# cslr_srio register map
Vendor: Texas Instruments
Registers are 32-bit, access not given, reset 0x0 unless marked. A register's access mark holds for its fields unless they carry their own. Offsets are as the file gives them; [hi:lo] are bit positions; {n}, {i} and the like mark numbered series.

## SRIO (part 2 of 2) — Rapid input/output
0x104C PE_LL_CTL reset 0x1 — Processing Element Logical Layer Control CSR
  [2:0] EXTENDED_ADDRESSING_CONTROL rw — Controls the number of address bits generated by the PE as a source and processed by the PE as the target of an operation. 0b100 - PE supports 66 bit addresses 0b010 - PE supports 50 bit addresses 0b001 - PE supports 34 bit addresses (default) All other encodings reserved
    4=66BIT (PE supports 66 bit addresses); 2=50BIT (PE supports 50 bit addresses); 1=34BIT (PE supports 34 bit addresses)
0x1058 LCL_CFG_HBAR — Local Configuration Space Base Address 0 CSR
  [30:0] LCSBA ro — For bits 30 to 15 Reserved for 34b addresses Reserved for 50b addresses Bits 66-51 of a 66b address For bits 14 to 0 Reserved for 34b addresses Bits 50-36 of a 50b address Bits 50-36 of a 66b address
0x105C LCL_CFG_BAR ro — Local Configuration Space Base Address 1 CSR
  [31:0] LCSBA — For bit 31 Reserved for 34b addresses Bit 35 of a 50b address Bit 35 of a 66b address For bits 30 to 0 Bits 34-3 of a 34b address, Bits 35-3 of a 50b address Bits 35-3 of a 66b address
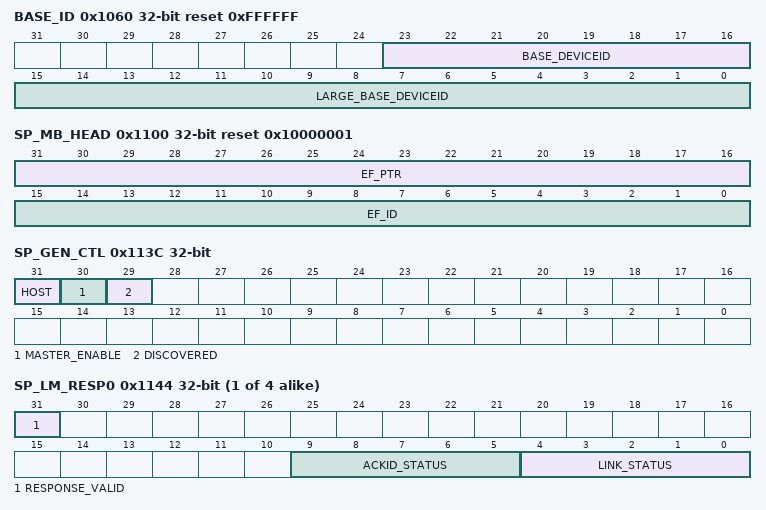
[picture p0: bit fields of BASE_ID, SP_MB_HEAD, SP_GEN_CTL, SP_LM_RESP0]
0x1060 BASE_ID reset 0xFFFFFF — Base Device ID CSR
  [23:16] BASE_DEVICEID rw — This is the base ID of the device in small common transport system (End points only)
  [15:0] LARGE_BASE_DEVICEID rw — This is the base ID of the device in a large common transport system (Only valid for end points, and if bit 4 of the PEFTR register is set)
0x1068 HOST_BASE_ID_LOCK reset 0xFFFF — Host Base Device ID Lock CSR
  [15:0] HOST_BASE_DEVICEID rw — This is the base ID for the Host PE that is initializing this PE
0x106C COMP_TAG rw — Component Tag CSR
  [31:0] COMPONENT_TAG — Software defined component Tag for PE. Useful for devices without device IDs
0x1100 SP_MB_HEAD ro reset 0x10000001 — 1x/4x LP-Serial Port Maintenance Block Header
  [31:16] EF_PTR — Hard wired pointer to the next block in the data structure.
  [15:0] EF_ID — Hard-wired extended features ID, 0x0001 - general endpoint device 0x0002 - general endpoint device with software assisted error recovery option. 0x0003 - Switch
0x1120 SP_LT_CTL reset 0xFFFFFF00 — Port Link Time-Out Control CSR
  [31:8] TIMEOUT_VALUE rw — Timeout value for all ports on the device. This timeout is for link events such as sending a packet to receiving the corresponding ACK. Max value represents 3-6 seconds.Timeout duration = 205nS * Timeout Value; Where, Timeout value is the decimal representation of this register value. FFFFFFh = 3.4 seconds 0FFFFFh = 215 ms 00FFFFh = 13.4 ms 000FFFh = 839.5 us 0000FFh = 52.3 us 00000Fh = 3.1 us 000001h = 205 ns for simulation only 000000h = Timer disabled
0x1124 SP_RT_CTL reset 0xFFFFFF00 — Port Response Time-Out Control CSR
  [31:8] TIMEOUT_VALUE rw — Timeout value for all ports on the device. This timeout is for sending a packet to receiving the corresponding response packet. Max value represents 3-6 seconds. The timeout duration can be expressed as:Timeout = 15 * ((Prescale value + 1) * DMA clock period * Timeout Value) Where, Prescale value is set in 0x0020 PSCR and the Timeout value is the decimal representation of this register value.
0x113C SP_GEN_CTL — Port General Control CSR
  [31] HOST rw — A Host device is a device that is responsible for system exploration, initialization, and maintenance. Agent or slave devices are typically initialized by Host devices. 0b0 - agent or slave device 0b1  host device
    0=DISABLE (Agent or Slave device); 1=ENABLE (Host device)
  [30] MASTER_ENABLE rw — The Master Enable bit controls whether or not a device is allowed to issue requests into the system. If the Master Enable is not set, the device may only respond to requests. 0b0 - processing element cannot issue requests 0b1 - processing element can issue requests
  [29] DISCOVERED rw — This device has been located by the processing element responsible for system configuration 0b0 - The device has not been previously discovered 0b1 - The device has been discovered by another processing element
{0x1140+0x20*i} SP_LM_REQ{i} (i=0..3) — Port Link Maintenance Request CSR
  [2:0] COMMAND rw — A write to this register generates a link-request control symbol on the corresponding port interface. Command to be sent in the link-request control symbol. If read, this field returns the last written value
{0x1144+0x20*i} SP_LM_RESP{i} (i=0..3) — Port Link Maintenance Response CSR
  [31] RESPONSE_VALID ro — If the link-request causes a link-response, this bit indicates that the link-response has been received and the status fields are valid.If the link-request does not cause a link-response, this bit indicates that the link-request has been transmitted.This bit automatically clears on read.
  [9:5] ACKID_STATUS ro — ackID status field from the link-response control symbol
  [4:0] LINK_STATUS ro — link status field from the link-response control symbol
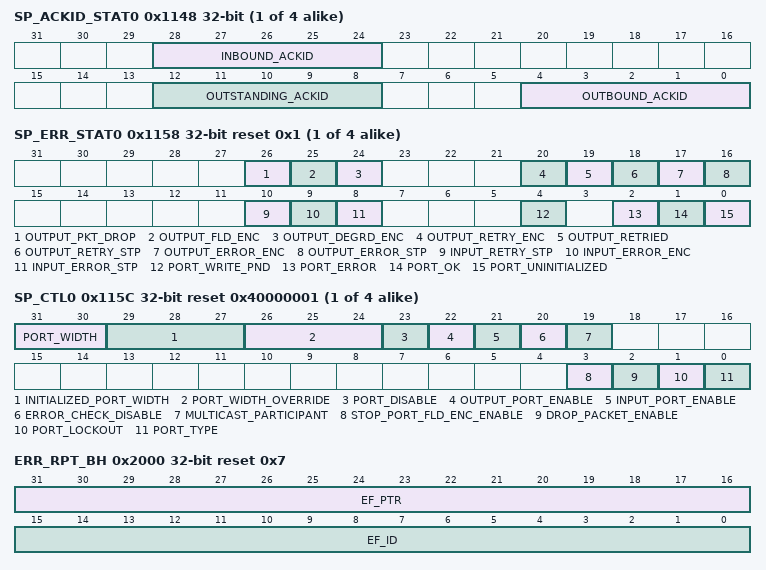
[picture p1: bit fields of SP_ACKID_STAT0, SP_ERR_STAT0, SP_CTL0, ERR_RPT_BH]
{0x1148+0x20*i} SP_ACKID_STAT{i} (i=0..3) — Port Local AckID Status CSR
  [28:24] INBOUND_ACKID rw — Input port next expected ackID value
  [12:8] OUTSTANDING_ACKID rw — Output port unacknowledged ackID status. Next expected acknowledge control symbol ackID field that indicates the ackID value expected in the next received acknowledge control symbol
  [4:0] OUTBOUND_ACKID rw — Output port next transmitted ackID value. Software writing this value can force retransmission of outstanding unacknowledged packets in order to manually implement error recovery
{0x1158+0x20*i} SP_ERR_STAT{i} reset 0x1 (i=0..3) — Port Error and Status CSR
  [26] OUTPUT_PKT_DROP rw — Output port has discarded a packet. (switch devices only)
  [25] OUTPUT_FLD_ENC rw — Output port has encountered a failed condition, meaning that the failed port error threshold has been reached in the Port n Error Rate Threshold register. Once set remains set until written with a logic 1 to clear
  [24] OUTPUT_DEGRD_ENC rw — Output port has encountered a degraded condition, meaning that the degraded port error threshold has been reached in the Port n Error Rate Threshold register. Once set remains set until written with a logic 1 to clear.
  [20] OUTPUT_RETRY_ENC rw — Output port has encountered a retry condition.This bit is set when bit 18 is set. Once set, remains set until written with a logic 1 to clear.
  [19] OUTPUT_RETRIED ro — Output port has received a packet-retry control symbol and can not make forward progress. This bit is set when bit 18 is set and is cleared when a packet-accepted or a packet-not-accepted control symbol is received (read-only).
  [18] OUTPUT_RETRY_STP ro — Output port has received a packet-retry control symbol and is in the "output retry-stopped" state (read-only).
  [17] OUTPUT_ERROR_ENC rw — Output port has encountered (and possibly recovered from) a transmission error. This bit is set when bit 16 is set. Once set, remains set until written with a logic 1 to clear
  [16] OUTPUT_ERROR_STP ro — Output is in the "output error-stopped" state (read-only).
  [10] INPUT_RETRY_STP ro — Input port is in the "input retry-stopped" state (read-only).
  [9] INPUT_ERROR_ENC rw — Input port has encountered (and possibly recovered from) a transmission error. This bit is set when bit 8 is set. Once set, remains set until written with a logic 1 to clear
  [8] INPUT_ERROR_STP ro — Input port is in the "input error-stopped" state (read-only).
  [4] PORT_WRITE_PND rw — Port has encountered a condition which required it to initiate a Maintenance Port-write operation This bit is only valid if the device is capable of issuing a maintenance port-write transaction. Once set remains set until written with a logic 1 to clear.
  [2] PORT_ERROR rw — Input or output port has encountered an error from which hardware was unable to recover. Once set, remains set until written with a logic 1 to clear.
  [1] PORT_OK ro — The input and output ports are initialized and the port is exchanging error-free control symbols with the attached device (read-only).
  [0] PORT_UNINITIALIZED ro — Input and output ports are not initialized. This bit and bit 1 are mutually exclusive (read-only
{0x115C+0x20*i} SP_CTL{i} reset 0x40000001 (i=0..3) — Port Control CSR
  [31:30] PORT_WIDTH ro — Hardware width of the port(read-only): 0b00 - Single-lane port 0b01 - Four-lane port 0b10 - 0b11  Reserved Only 0b00 is valid for SP1, SP2, and SP3
  [29:27] INITIALIZED_PORT_WIDTH ro — Width of the ports after initialized (read only): 0b000 - Single-lane port, lane 0 0b001 - Single-lane port, lane 2 0b010 - Four-lane port 0b011 - 0b111 - Reserved
  [26:24] PORT_WIDTH_OVERRIDE rw — Soft port configuration to override the hardware size: 0b000 - No override 0b001 - Reserved 0b010 - Force single lane, lane 0 0b011 - Force single lane, lane 2 0b100 - 0b111 - Reserved
    0=NO_OVERRIDE; 2=SINGLE_LANE_0 (Force single lane, lane 0); 3=SINGLE_LANE_2 (Force single lane, lane 2)
  [23] PORT_DISABLE rw — 0b0 - port receivers/drivers are enabled 0b1 - port receivers/drivers are disabled and are unable to receive/transmit to any packets or control symbols
  [22] OUTPUT_PORT_ENABLE rw — 0b0 - port is stopped and not enabled to issue any packets except to route or respond to I/O logical MAINTENANCE packets, depending upon the functionality of the processing element. Control symbols are not affected and are sent normally. 0b1 - port is enabled to issue any packets
  [21] INPUT_PORT_ENABLE rw — Input port receive enable: 0b0 - port is stopped and only enabled to route or respond I/O logical MAINTENANCE packets, depending upon the functionality of the processing element 0b1 - port is enabled to respond to any packet
  [20] ERROR_CHECK_DISABLE rw — This bit disables all RapidIO transmission error checking0b0 - Error checking and recovery is enabled 0b1 - Error checking and recovery is disabled
  [19] MULTICAST_PARTICIPANT ro — Send incoming Multi cast-event control symbols to this port (multiple port devices only)
  [3] STOP_PORT_FLD_ENC_ENABLE rw — When set, this bit causes the port to set the Port Error bit in the Port n Error and Status CSR and stop attempting to send packets to the connected device when the Output Failed-encountered bit is set. Packets are discarded if the Drop Packet Enable bit is set. When cleared the port continues to attempt to transmit packets to the connected device if the Output Failed-encountered bit is set.
  [2] DROP_PACKET_ENABLE rw — When set this bit allows the output port to drop packets that are acknowledged with a packet-not-accepted control symbol when the error failed threshold is exceeded. If the port "heals", and the current error rate falls below the failed threshold, the output no longer drops packets. (switch devices only) When cleared, the output port continues to try to transmit packets that have been rejected due to transmission errors
  [1] PORT_LOCKOUT rw — Port Lockout:When cleared, this port is enabled to issue any packets When set, this port is stopped and is not enabled to issue or receive any packets; the input port can still follow the training procedure and can still send and respond to link-requests; all received packets return packet-not-accepted control symbols to force an error condition to be signaled by the sending device
  [0] PORT_TYPE ro — This indicates the port type, parallel or serial (read only) 0b0 - Parallel port 0b1 - Serial port
0x2000 ERR_RPT_BH ro reset 0x7 — Error Reporting Block Header
  [31:16] EF_PTR — Hard wired pointer to the next block in the data structure. NONE EXISTS
  [15:0] EF_ID — Hard wired Extended Features ID
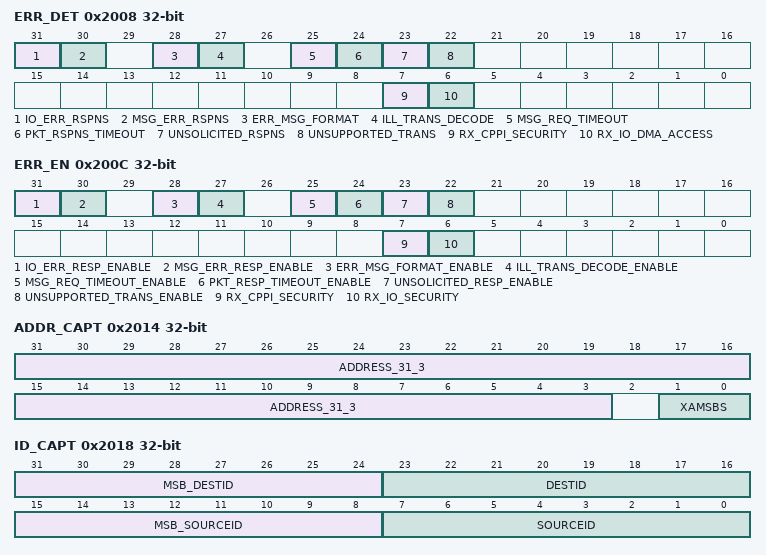
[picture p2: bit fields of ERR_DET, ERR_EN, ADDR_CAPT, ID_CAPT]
0x2008 ERR_DET — Logical/Transport Layer Error Detect CSR
  [31] IO_ERR_RSPNS rw — Received a response of 'ERROR' for an IO Logical Layer Request. (end point device only) Write 0 to clear
  [30] MSG_ERR_RSPNS rw — Received a response of 'ERROR' for an MSG Logical Layer Request. (end point device only) Write 0 to clear
  [28] ERR_MSG_FORMAT rw — Received MESSAGE packet data payload with an invalid size or segment (MSG logical) (end point device only)Write 0 to clear
  [27] ILL_TRANS_DECODE rw
  [25] MSG_REQ_TIMEOUT rw — A required message request has not been received within the specified time-out interval (MSG logical) (end point device only) Write 0 to clear
  [24] PKT_RSPNS_TIMEOUT rw — A required response has not been received within the specified timeout interval (IO/MSG/GSM logical) (end point device only) Write 0 to clear
  [23] UNSOLICITED_RSPNS rw — An unsolicited/unexpected Response packet was received (IO/MSG/GSM logical; only Maintenance response for switches) (switch or endpoint device) Write 0 to clear
  [22] UNSUPPORTED_TRANS rw — A transaction is received that is not supported in the Destination Operations CAR (IO/MSG/GSM logical; only Maintenance port-write for switches) (switch or endpoint device) Write 0 to clear
  [7] RX_CPPI_SECURITY rw — Access to one of the RX queues was blocked Write 0 to clear
  [6] RX_IO_DMA_ACCESS rw — DMA access to MAU was blocked Write 0 to clear
0x200C ERR_EN — Logical/Transport Layer Error Enable CSR
  [31] IO_ERR_RESP_ENABLE rw — Enable reporting of an IO error response. Save and Lock capture information in appropriate Logical/Transport Layer Capture CSRs. (end point device only)
  [30] MSG_ERR_RESP_ENABLE rw — Enable reporting of a Message error response. Save and Lock capture information in appropriate Logical/Transport Layer Capture CSRs.(end point device only)
  [28] ERR_MSG_FORMAT_ENABLE rw — Enable reporting of a message format error. Save and lock transaction capture information in Logical/Transport Layer Device ID and Control Capture CSRs. (end point device only)
  [27] ILL_TRANS_DECODE_ENABLE rw — Enable reporting of an illegal transaction decode error. Save and Lock capture information in Logical/Transport Layer Device ID and Control Capture CSRs. (switch or end-point device)
  [25] MSG_REQ_TIMEOUT_ENABLE rw — Enable reporting of a Message Request time-out error. Save and lock transaction capture information in Logical/Transport Layer Device ID and Control Capture CSRs for the last Message request segment packet received. (end point device only)
  [24] PKT_RESP_TIMEOUT_ENABLE rw — Enable reporting of a packet response time-out error. Save and lock original request address in Logical/Transport Layer Address Capture CSRs. Save and lock original request Destination ID in Logical/Transport Layer Device ID Capture CSR. (end point device only).
  [23] UNSOLICITED_RESP_ENABLE rw — Enable reporting of an unsolicited response error. Save and Lock capture information in Logical/Transport Layer Device ID and Control Capture CSRs. (switch or end-point device)
  [22] UNSUPPORTED_TRANS_ENABLE rw — Enable reporting of an unsupported transaction error. Save and Lock capture information in Logical/Transport Layer Device ID and Control Capture CSRs. (switch or end-point device)
  [7] RX_CPPI_SECURITY rw — Enable reporting of attempt at unauthorized access to a RX queue. Save and Lock capture information in appropriate Logical/Transport Layer Capture CSRs.
  [6] RX_IO_SECURITY rw — Enable reporting of attempt at unauthorized memory location access. Save and Lock capture information in appropriate Logical/Transport Layer Capture CSRs.
0x2010 H_ADDR_CAPT ro — Logical/Transport Layer High Address Capture CSR
  [31:0] ADDRESS_63_32 — Most Significant 32 bits of the address associated with the error(only valid for devices supporting 66 and 50 bit addresses)
0x2014 ADDR_CAPT — Logical/Transport Layer Address Capture CSR
  [31:3] ADDRESS_31_3 ro — Least Significant 29 bits of the address associated with the error
  [1:0] XAMSBS ro — Extended address bits of the address associated with the error
0x2018 ID_CAPT ro — Logical/Transport Layer Device ID Capture CSR
  [31:24] MSB_DESTID — Most significant byte of the destinationID associated with the error (large transport systems only)
  [23:16] DESTID — The destinationID associated with the error
  [15:8] MSB_SOURCEID — Most significant byte of the source ID associated with the error (large transport systems only)
  [7:0] SOURCEID — The sourceID associated with the error
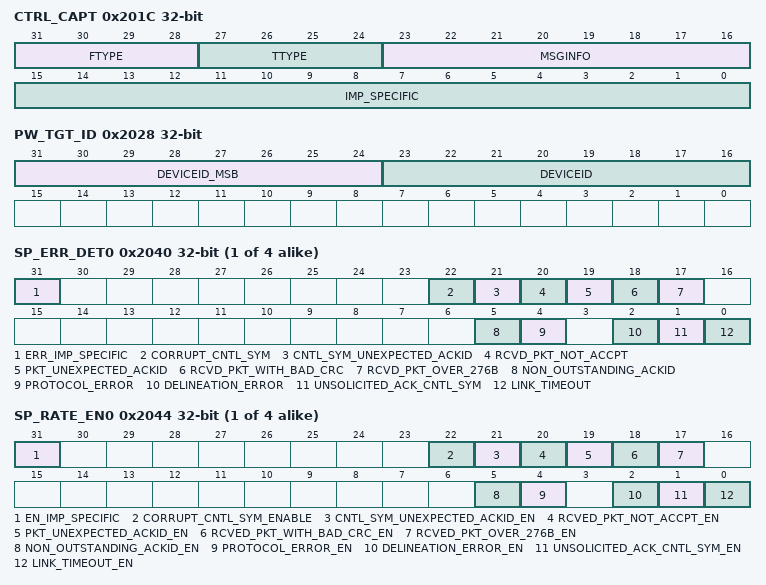
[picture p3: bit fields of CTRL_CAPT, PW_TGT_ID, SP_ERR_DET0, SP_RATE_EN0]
0x201C CTRL_CAPT ro — Logical/Transport Layer Control Capture CSR
  [31:28] FTYPE — Format type associated with the error
  [27:24] TTYPE — Transaction type associated with the error
  [23:16] MSGINFO — letter, mbox, and msgseg for the last Message request received for the mailbox that had an error (Message errors only)
  [15:0] IMP_SPECIFIC — Implementation specific information associated with the error
0x2028 PW_TGT_ID — Port-Write Target Device ID CSR
  [31:24] DEVICEID_MSB rw — This is the most significant byte of the port-write target device ID (large transport systems only)
  [23:16] DEVICEID rw — This is the port-write target deviceID
{0x2040+0x40*i} SP_ERR_DET{i} (i=0..3) — Port Error Detect CSR
  [31] ERR_IMP_SPECIFIC rw — An implementation specific error has been detected. It covers illegal field of Maintenance packet error, illegal destination ID, not supported transaction.
  [22] CORRUPT_CNTL_SYM rw — Received a control symbol with a bad CRC value (serial)
  [21] CNTL_SYM_UNEXPECTED_ACKID rw — Received an acknowledge control symbol with an unexpected ackID (packet-accepted or packet_retry). The Capture registers don't have valid information during this error detection
  [20] RCVD_PKT_NOT_ACCPT rw — Received packet-not-accepted acknowledge control symbol
  [19] PKT_UNEXPECTED_ACKID rw — Received packet with unexpected ackID value - out-of-sequence ackID
  [18] RCVD_PKT_WITH_BAD_CRC rw — Received packet with a bad CRC value
  [17] RCVD_PKT_OVER_276B rw — Received packet which exceeds the maximum allowed size
  [5] NON_OUTSTANDING_ACKID rw — Link_response received with an ackID that is not outstanding. The Capture registers don't have valid information during this error detection
  [4] PROTOCOL_ERROR rw — An unexpected packet or control symbol was received
  [2] DELINEATION_ERROR ro — Received unaligned /SC/ or /PD/ or undefined code-group (serial). The Capture registers don't have valid information during this error detection
  [1] UNSOLICITED_ACK_CNTL_SYM rw — An unexpected acknowledge control symbol was received
  [0] LINK_TIMEOUT rw — An acknowledge or link-response control symbol is not received within the specified time-out interval. The Capture registers don't have valid information during this error detection.
{0x2044+0x40*i} SP_RATE_EN{i} (i=0..3) — Port Error Enable CSR
  [31] EN_IMP_SPECIFIC rw — Enable error rate counting of implementation specific errors
  [22] CORRUPT_CNTL_SYM_ENABLE rw — Enable error rate counting of a corrupt control symbol
  [21] CNTL_SYM_UNEXPECTED_ACKID_EN rw — Enable error rate counting of an acknowledge control symbol with an unexpected ackID
  [20] RCVED_PKT_NOT_ACCPT_EN rw — Enable error rate counting of received packet-not-accepted control symbols
  [19] PKT_UNEXPECTED_ACKID_EN rw — Enable error rate counting of packet with unexpected ackID value - out-of-sequence ackID
  [18] RCVED_PKT_WITH_BAD_CRC_EN rw — Enable error rate counting of packet with a bad CRC value
  [17] RCVED_PKT_OVER_276B_EN rw — Enable error rate counting of packet which exceeds the maximum allowed size
  [5] NON_OUTSTANDING_ACKID_EN rw — Enable error rate counting of link-responses received with an ackID that is not outstanding
  [4] PROTOCOL_ERROR_EN rw — Enable error rate counting of protocol errors
  [2] DELINEATION_ERROR_EN rw — Enable error rate counting of delineation errors
  [1] UNSOLICITED_ACK_CNTL_SYM_EN rw — Enable error rate counting of unsolicited acknowledge control symbol errors
  [0] LINK_TIMEOUT_EN rw — Enable error rate counting of link time-out errors
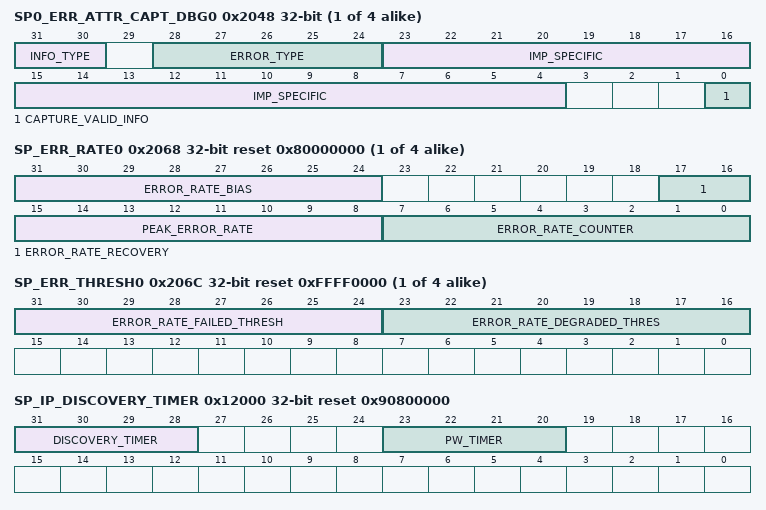
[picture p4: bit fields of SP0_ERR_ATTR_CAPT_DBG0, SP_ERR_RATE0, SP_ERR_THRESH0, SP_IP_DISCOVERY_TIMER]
{0x2048+0x40*i} SP{i}_ERR_ATTR_CAPT_DBG0 (i=0..3) — Port Attributes Error Capture CSR
  [31:30] INFO_TYPE ro — Type of information logged 00 - packet 01 - control symbol (only error capture register 0 is valid) 10 - implementation specific (capture register contents are implementation specific) 11 - undefined (S-bit error), capture as if a packet (parallel physical layer only)
  [28:24] ERROR_TYPE ro — Encoded value of captured error bit in the Port n Error Detect Register
  [23:4] IMP_SPECIFIC ro — Implementation Dependent Error Information
  [0] CAPTURE_VALID_INFO rw — This bit is set by hardware to indicate that the Packet/control symbol capture registers contain valid information. For control symbols, only capture register 0 will contain meaningful information. The software write "0" to clear this bit and subsequently unlock all capture registers of port n
{0x204C+0x40*i} SP{i}_ERR_CAPT_DBG[4] ro (i=0..3) — Port Packet/Control Symbol Error Capture CSR
  [31:0] CAPTURE — Control Character and Control Symbol or 0 to 3 Bytes of Packet Header
{0x2068+0x40*i} SP_ERR_RATE{i} reset 0x80000000 (i=0..3) — Port Error Rate CSR
  [31:24] ERROR_RATE_BIAS rw — These bits provide the error rate bias value 0x00 - do not decrement the error rate counter 0x01 - decrement every 1ms (nominal) 0x03 - decrement every 10ms (nominal) 0x07 - decrement every 100ms 0x0F - decrement every 1s (nominal) 0x1F - decrement every 10s (nominal) 0x3F - decrement every 100s (nominal) 0x7F - decrement every 1000s (nominal) 0xFF - decrement every 10000s (nominal) other values are reserved
  [17:16] ERROR_RATE_RECOVERY rw — These bits limit the incrementing of the error rate counter above the failed threshold trigger.0b00 - only count 2 errors above 0b01 - only count 4 errors above 0b10 - only count 16 error above 0b11 - do not limit incrementing the error rate count
  [15:8] PEAK_ERROR_RATE rw — This field contains the peak value attained by the error rate counter
  [7:0] ERROR_RATE_COUNTER rw — These bits maintain a count of the number of transmission error that have occurred. If this value equals the value contained in the error rate threshold trigger register, then an error will be reported.
{0x206C+0x40*i} SP_ERR_THRESH{i} reset 0xFFFF0000 (i=0..3) — Port Error Rate Threshold CSR
  [31:24] ERROR_RATE_FAILED_THRESH rw — These bits provide the threshold value for reporting an error condition due to a possibly broken link.0x00 - Disable the error rate register 0x01 - Set the error reporting threshold to 1 0x02 - Set the error reporting threshold to 2 ... 0xFF - Set the error reporting threshold to 255
  [23:16] ERROR_RATE_DEGRADED_THRES rw — These bits provide the threshold value for reporting an error condition due to a degrading link.0x00 - Disable the error rate register 0x01 - Set the error reporting threshold to 1 0x02 - Set the error reporting threshold to 2 ... 0xFF - Set the error reporting threshold to 255
0x12000 SP_IP_DISCOVERY_TIMER reset 0x90800000 — Port IP Discovery Timer in 4x mode
  [31:28] DISCOVERY_TIMER rw — Discovery Timer in 4x mode. The discovery-timer allows time for the link partner to enter its DISCOVERY state and if the link partner is supporting 4x mode, for all 4 lanes to be aligned. 0000b: 102.4pS, for debug only 0001b: 0.84ms 0010b: 0.84ms * 2 = 1.68ms .. 1001b: 0.84ms * 9= 7.56ms (default) ... 1111b: 0.84ms *15= 12.6ms
  [23:20] PW_TIMER rw — Port-Write Timer . The timer defines a period to repeat sending an error reporting Port-Write request for software assistance. The timer stopped by software writing to the error detect registers 0000b: Disabled. Port-Write is sent once only 0001b: 107ms - 214ms 0010b: 214ms - 321ms 0100b: 428ms - 535ms 1000b: 856ms - 963ms (default) 1111b: 0.82-1.64us -for debug only Other  reserved
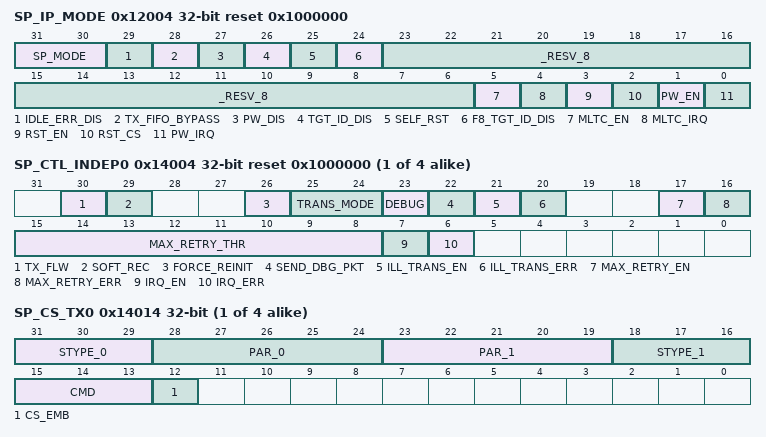
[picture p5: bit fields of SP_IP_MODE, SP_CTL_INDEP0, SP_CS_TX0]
0x12004 SP_IP_MODE reset 0x1000000 — Port IP Mode CSR
  [31:30] SP_MODE ro — SRIO Port IP Mode of operation: 00 - 1x/4x LP-Serial RapidIO Specification 01 - 4 ports (1x mode each) 10 - reserved 11 - reserved
  [29] IDLE_ERR_DIS rw — IDLE Error checking disable 1 - error checking disabled, all not idle or invalid characters during idle sequence are ignored 0 - error checking enabled (default), only |K|, |A| and |R| characters are available. If input receive any other characters in idle sequence it should enter the Input-Error-stopped state
    1=DISABLE (Error checking disabled); 0=ENABLE (Error checking enabled)
  [28] TX_FIFO_BYPASS rw — TX_ FIFO_BYPASS 0  The TX_FIFO is operational (Default) 1 - Transmit FIFO is bypassed The txbclk and the sys_clk maust be locked during operation, but the phase variation up to 1 clock cycle is allowable. The 4 deep FIFO is used to accommodate the phase difference
    0=DISABLE (The TX_FIFO is operational (Default)); 1=ENABLE (The TX_FIFO is bypassed)
  [27] PW_DIS rw — Port_Write Disable 0 = Port-Write Error reporting is enabled(default) 1 = Port-Write is disabled
    1=DISABLE (Disable Port-Write Error reporting); 0=ENABLE (Enable Port-Write Error reporting)
  [26] TGT_ID_DIS ro — Destination ID Decode Disable - Definition of packet acception by the physical layer 0 -packet accepted if DestID = Base ID When DestID is not equal to Base ID, the packet is ignored, i.e. it accepted by RapidIO port but is not forwarded to logical layer 1 - packet accepted with any DestID and forwarded to the logical layer.
  [25] SELF_RST rw — Self reset enable, when 4 Link-Request Reset Control Symbols are accepted 0 = Disable (Default),interrupt signal is asserted 1 = Enable, the reset signal is asserted by the SRIO_TE reset controller. The SRIO_TE configuration registers are set to the default value after reset and loose a boot initialization values.
    0=DISABLE (Self reset interrupt disable); 1=ENABLE (Self reset interrupt enable)
  [24] F8_TGT_ID_DIS rw — Physical Layer Disable. This bit only disables the Ftype8 (Maintenance Packet) checking at the physical layer
    0=DISABLE (Non-matching Ftype8 packets are forwarded to MAC layer.); 1=ENABLE (Regardless of Ftype8 packet destination ID, the physical layer accepts and handles the Maintenance request packets.)
  [23:6] _RESV_8 — (access N)
  [5] MLTC_EN rw — Multicast-Event Interrupt Enable . If enabled, the interrupt signal is High when the Multicast-Event control symbol is received by any port.
    0=DISABLE (Multicast interrupt disable); 1=ENABLE (Multicast interrupt enable)
  [4] MLTC_IRQ — Multicast-Event Interrupt Status bit.It is High when the Multicast-Event control symbol is received by any port. Once set, remains set until written with logic 1 to clear. The mltc_irq output signal is driven by this bit (access RC)
  [3] RST_EN rw — Reset Interrupt Enable . If enabled, the interrupt signal is High when the 4 reset control symbols are received in a sequence
    0=DISABLE (Reset interrupt disable); 1=ENABLE (Reset interrupt enable)
  [2] RST_CS — Reset received status bit. It is set when 4 reset control symbols are received in a sequence. Once set, remains set until written with logic 1 to clear. The rst_irq output signal is driven by this bit (access RC)
  [1] PW_EN rw — Port-Write-In Interrupt Enable . If enabled, the interrupt signal is High when the Port-Write_In request is received
    0=DISABLE (Port-Write-In interrupt disable); 1=ENABLE (Port-Write-In interrupt enable)
  [0] PW_IRQ — Port-Write-In Request interrupt is set when the Port-Write_In request is received. The payload is captured. Once set, remains set until written with logic 1 to clear. The pw_irq output signal is driven by this bit (access RC)
0x12008 IP_PRESCAL reset 0xF — Serial Port IP Prescalar
  [7:0] PRESCALE rw — For different frequencies of the DMA clock, use the formula: [DMA freq * 16/156.25 - 1] to get the prescalar value in decimal, where DMA freq is in MHz 06h - 66.67 MHz 09h - 100MHz 10h - 166.67MHz -- 18h - 250MHz -- 21h  333Mhz
0x12010 SP_IP_PW_IN_CAPT[4] ro — Port-Write-In Capture CSR
  [31:0] PW_CAPT — Port-Write payload: word n
{0x14000+0x100*i} SP_RST_OPT{i} (reset mask 0xFFFFFF00) (i=0..3) — Port Reset Option CSR
  [7:0] PORT_ID ro — Port ID defines unique number for port in Switch. The Port ID is used for Port_Write request. The ID coincides with ISF port of connection. Example: 00_0000_01 - port 1 ( Impl.: IP0, port 1) 00_0001_11 - port 7 ( Impl.: IP1, port 3)
{0x14004+0x100*i} SP_CTL_INDEP{i} reset 0x1000000 (i=0..3) — Port Control Independent register
  [30] TX_FLW rw — Transmit Link Flow Control enable 0 - Receive link flow control 1 - Transmit link flow control ( not supported)
    0=DISABLE (Disables transmit flow control (Enables receive flow control))
  [29] SOFT_REC rw — Software controlled error recovery 0 - Hardware 1 - Software By default the transmission error recovery sequence is performed by the hardware.
    0=BYHARDWARE (Transmission of error recovery sequence is performed by the hardware); 1=BYSOFTWARE (Transmission of error recovery sequence is performed by the software)
  [26] FORCE_REINIT wo — Force reinitialization process. In 4x mode this bit affects all 4 lanes. This bit is write only, read always "0"
  [25:24] TRANS_MODE rw — Describe the transfer mode for each port 00 : Reserved (Cut-Through Mode) 01 : Store & Forward Mode 1x: Reserved
  [23] DEBUG rw — Mode of operation 0 - Normal 1 - debug mode. The Debug mode unlocks capture registers for write and enable debug packet generator feature
    0=NORMAL (Normal mode); 1=DEBUG (Debug mode)
  [22] SEND_DBG_PKT rw — Send Debug_packet Write 1 force to send debug packet. This bit is set by software and cleared after debug packet is sent. Writes when the bit is set are ignored. Debug mode only
  [21] ILL_TRANS_EN rw — Illegal Transfer Error reporting Enable. If enabled, the Port-Write and interrupt are reported error
    0=DISABLE (Disables Illegal Transfer Error reporting); 1=ENABLE (Enables Illegal Transfer Error reporting)
  [20] ILL_TRANS_ERR rw — Illegal Transfer Error
  [17] MAX_RETRY_EN rw — Max_retry_error report enable. If enabled, the Port-Write and interrupt are reported as error
    1=ENABLE (Max retry error report enable); 0=DISABLE (Max retry error report disable)
  [16] MAX_RETRY_ERR rw — Max-retry_error bit is set when max_retry_cnt is equal to max_retry_threshold . The Port-Write request and interrupt are generated if enabled. This bit is ignored if max_retry threshold is 00. Once set, remains set until written with logic 1 to clear. This bit also is cleared by writing all 0 to the register "RIO_SP0_ERR_DET". This error also reported in registers: "RIO_SP0_ERR_DET".
  [15:8] MAX_RETRY_THR rw — Maximum Retry Threshold Trigger These bits provide the threshold value for reporting an error condition due to possibly broken partner behavior. 00 - disable the max_retry_error reporting 01 - set the max_retry_threshold to 1 02 - set the max_retry_threshold to 2 ... FF - set the max_retry_threshold to 255
    0=DISABLE (Disable the max_retry_error reporting)
  [7] IRQ_EN rw — Interrupt error report Enable . If enabled, the interrupt signal is High when the IRQ_ERR is set to 1
    1=ENABLE (Interrupt error report enable); 0=DISABLE (Interrupt error report disable)
  [6] IRQ_ERR rw — The Interrupt Error Status bit. It is set to one if an error occurs and there is a Port_Write condition. Once set, remains set until written with logic 1 to clear
{0x14008+0x100*i} SP_SILENCE_TIMER{i} reset 0xB0000000 (i=0..3) — Port Silence Timer
  [31:28] SILENCE_TIMER rw — Silence timer. Defines the time of the port in the SILENT state. 0000b: 64ns for debug 0001b: 13.1us 0010b: 13.1us * 2 = 26.2us .. 1011b: 13.1us * 11 = 144.1us default ... 1111b: 13.1us *15= 196.5us
{0x1400C+0x100*i} SP_MULT_EVNT_CS{i} wo (i=0..3) — Port Multicast-Event Control Symbol Request register
  [31:0] MULT_EVNT_CS — Write to send Control Symbol, data is ignored. read - 0x000000
{0x14014+0x100*i} SP_CS_TX{i} (i=0..3) — Port Control Symbol Transmit
  [31:29] STYPE_0 rw — Encoding for control symbol that make use of parameters PAR_0 and PAR_1
  [28:24] PAR_0 rw — Used in conjunction with stype0 encoding
  [23:19] PAR_1 rw — Used in conjunction with stype0 encoding
  [18:16] STYPE_1 rw — Encoding for control symbol that make use of parameter CMD
  [15:13] CMD rw — Used in conjunction with stype1 encoding to define the link maintenance commands
  [12] CS_EMB rw — When set, force the outbound flow to insert control symbol into packet. Used in debug mode
